AUTOSAR XML (schema 4-3-1)
package /TPC_Composition/Components
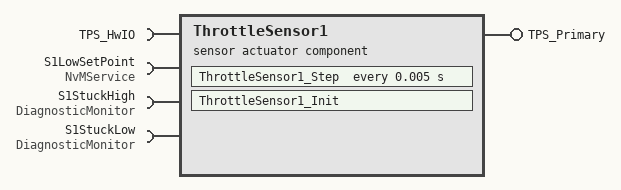
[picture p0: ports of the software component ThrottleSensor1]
  sensor actuator sw component type ThrottleSensor1
    require port TPS_HwIO: nonqueued-receiver-com-spec{data-element=Value, init-value=0}, required-interface=TPS_HwIO
    provide port TPS_Primary: nonqueued-sender-com-spec{data-element=Value, init-value=0}, provided-interface=TPS_Primary
    require port S1LowSetPoint: required-interface=NvMService
    require port S1StuckHigh: required-interface=DiagnosticMonitor
    require port S1StuckLow: required-interface=DiagnosticMonitor
    behavior ThrottleSensor1_IB: data-type-mapping=ThrottleSensor1DataTypeMappingsSet, handle-termination-and-restart=NO-SUPPORT
      ar-typed-per-instance-memorys:
        data autosar_tpc_throttl_LowSetPoint: category=VALUE, sw-calibration-access=READ-ONLY, type=uint8
      timing event Event_ThrottleSensor1_Step: start-on-event=ThrottleSensor1_Step, period=0.005
      runnable ThrottleSensor1_Init
        async call SC_S1LowSetPoint_ReadBlock: operation=S1LowSetPoint.ReadBlock, timeout=1
      runnable ThrottleSensor1_Step
        data-read-access:
          access IN_TPS_HwIO_Value: accessed-variable=TPS_HwIO.Value
        data-write-access:
          access OUT_TPS_Primary_Value: accessed-variable=TPS_Primary.Value
        parameter access SCALPRM_TPSPrimaryPercent_LkupTbl: accessed-parameter=TPSPrimaryPercent_LkupTbl
        sync call SC_S1StuckHigh_SetEventStatus: operation=S1StuckHigh.SetEventStatus, timeout=1.0E-06
        sync call SC_S1StuckLow_SetEventStatus: operation=S1StuckLow.SetEventStatus, timeout=1.0E-06
      shared-parameters:
        parameter data prototype TPSPrimaryPercent_LkupTbl: category=CURVE, sw-calibration-access=READ-WRITE, type=Appl_TPSPrimaryPercent_LkupTbl, init-value=constant-reference={short-label=TPSPrimaryPercent_LkupTbl, constant=TPSPrimaryPercent_LkupTbl}
